# A31S13x register map
Vendor: VENDOR ABOV Semiconductor Co., Ltd.; Series: A31S13x; File version: 1.0
CPU: CM0+ r0p1, little endian, no MPU, no FPU, VTOR, 2 interrupt priority bits
Registers are 32-bit, read-write, reset 0x0 unless marked. A register's access mark holds for its fields unless they carry their own. Offsets are from the block's base; [hi:lo] are bit positions.

## SCUCC — System Control Unit: Chip Configuration
Base 0x4000F000
0x00 VENDORID ro reset 0x41424F56 — Vendor Identification Register
  [31:0] VENDID — Vendor Identification
0x04 CHIPID ro reset 0x53311340 (reset mask 0xFFFFFFF0) — Chip Identification Register
  [31:0] CHIPID — Chip Identification
0x08 REVNR ro (reset mask 0xFFFFFF00) — Revision Number Register
  [7:0] REVNO — Chip Revision Number
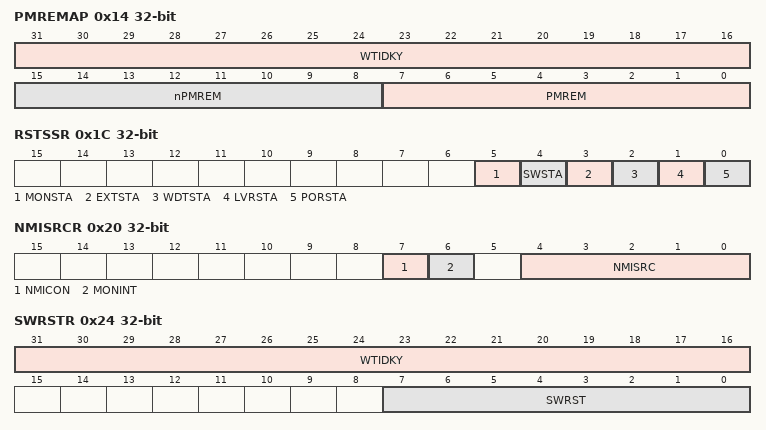
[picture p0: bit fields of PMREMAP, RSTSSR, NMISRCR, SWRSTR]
0x14 PMREMAP — Program Memory Remap Register
  [31:16] WTIDKY wo — Write Identification Key (0xe2f1)
    0xE2F1=Value (Key Value (0xe2f1))
  [15:8] nPMREM wo — Write Complement Key
    150=Boot ROM is re-mapped to address 0x0. (0x96); 0=Flash Memory is re-mapped to address 0x0
  [7:0] PMREM — Program Memory Remap
    105=Boot ROM is re-mapped to address 0x0. (0x69); 0=Flash Memory is re-mapped to address 0x0
0x1C RSTSSR (reset mask 0xFFFFFFC0) — Reset Source Status Register
  [5] MONSTA — Clock Monitoring Reset Status
    0=NotDetected; 1=Detected (CMR was detected.)
  [4] SWSTA — Software Reset Status
    0=NotDetected; 1=Detected (SWR was detected.)
  [3] EXTSTA — External Pin Reset Status
    0=NotDetected; 1=Detected (EXTR was detected.)
  [2] WDTSTA — Watch-Dog Timer Reset Status
    0=NotDetected; 1=Detected (WDTR was detected.)
  [1] LVRSTA — LVR Reset Status
    0=NotDetected; 1=Detected (LVR was detected.)
  [0] PORSTA — POR Reset Status
    0=NotDetected; 1=Detected (POR was detected.)
0x20 NMISRCR — NMI Source Selection Register
  [7] NMICON — Non-Maskable Interrupt (NMI) Control
    0=Disable NMI; 1=Enable NMI
  [6] MONINT — Clock Monitoring Interrupt Selection
    0=NotSelect (Non-select clock monitoring interrupt for NMI source.); 1=Select clock monitoring interrupt for NMI source
  [4:0] NMISRC — Non-Maskable Interrupt Source Selection
0x24 SWRSTR wo — Software Reset Register
  [31:16] WTIDKY — Write Identification Key (0x9eb3)
    0x9EB3=Value (Key Value (0x9eb3))
  [7:0] SWRST — Software Reset (System Reset)
    45=Generate (A software reset will be generated for all peripheral and core. (0x2d)); 0=NoEffect
0x28 SRSTVR ro reset 0x55 — System Reset Validation Register
  [7:0] VALID — System Reset Validation
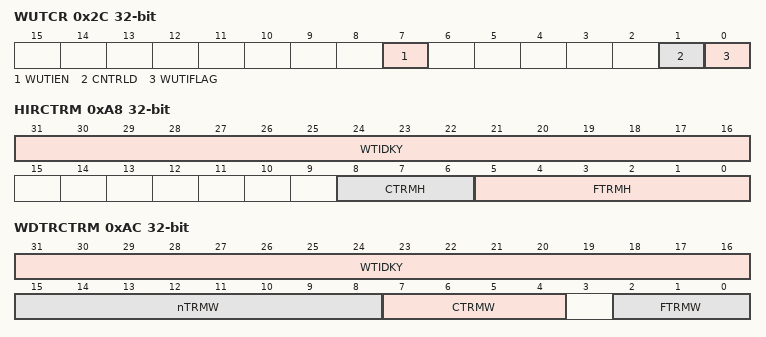
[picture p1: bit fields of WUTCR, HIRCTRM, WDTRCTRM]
0x2C WUTCR — Wake-Up Timer Control Register
  [7] WUTIEN — Wake-Up Timer Interrupt Enable
    0=Disable Wake-Up Timer interrupt; 1=Enable Wake-Up Timer interrupt
  [1] CNTRLD — Counter Reload
    0=NoEffect; 1=Reload data to counter
  [0] WUTIFLAG — Wake-Up Timer Interrupt Flag
    0=No request occurred; 1=Request occurred
0x30 WUTDR reset 0xFA — Wake-Up Timer Data Register
  [15:0] WUTDATA — Wake-Up Timer Data
0xA8 HIRCTRM (reset mask 0xFFFFFE00) — High Frequency Internal RC Trim Register (HIRCNFIG)
  [31:16] WTIDKY wo — Write Identification Key (0xa6b5)
    0xA6B5=Value (Key Value (0xa6b5))
  [8:6] CTRMH — Factory HIRC Coarse Trim
  [5:0] FTRMH — Factory HIRC Fine Trim
0xAC WDTRCTRM (reset mask 0xFFFFFF08) — Watch-Dog Timer RC Trim Register (WDTRCNFIG)
  [31:16] WTIDKY wo — Write Identification Key (0x4c3d)
    0x4C3D=Value (Key Value (0x4c3d))
  [15:8] nTRMW wo — Write Complement Key
  [7:4] CTRMW — Factory WDTRC Coarse Trim
  [2:0] FTRMW — Factory WDTRC Fine Trim

## SCULV — System Control Unit: LVI and LVR
Base 0x40005100
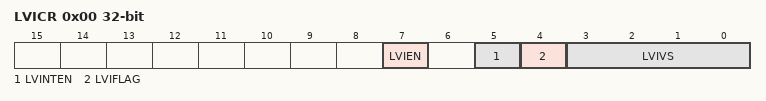
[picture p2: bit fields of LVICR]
0x00 LVICR — Low Voltage Indicator Control Register
  [7] LVIEN — LVI Enable
    0=Disable low voltage indicator; 1=Enable low voltage indicator
  [5] LVINTEN — LVI Interrupt Enable
    0=Disable low voltage indicator interrupt; 1=Enable low voltage indicator interrupt
  [4] LVIFLAG — LVI Interrupt Flag
    0=No request occurred; 1=Request occurred
  [3:0] LVIVS — LVI Voltage Selection
    3=DNW3 (Do not write.); 4=2p00V (2.00V); 5=2p13V (2.13V); 6=2p28V (2.28V); 7=2p46V (2.46V); 8=2p67V (2.67V); 9=3p04V (3.04V); 10=3p20V (3.20V); 11=3p55V (3.55V); 12=3p75V (3.75V); 13=3p99V (3.99V); 14=4p25V (4.25V); 15=4p55V (4.55V)
0x04 LVRCR — Low Voltage Reset Control Register
  [7:0] LVREN — LVR Enable
    85=Disable low voltage reset. (0x55); 0=Enable low voltage reset
